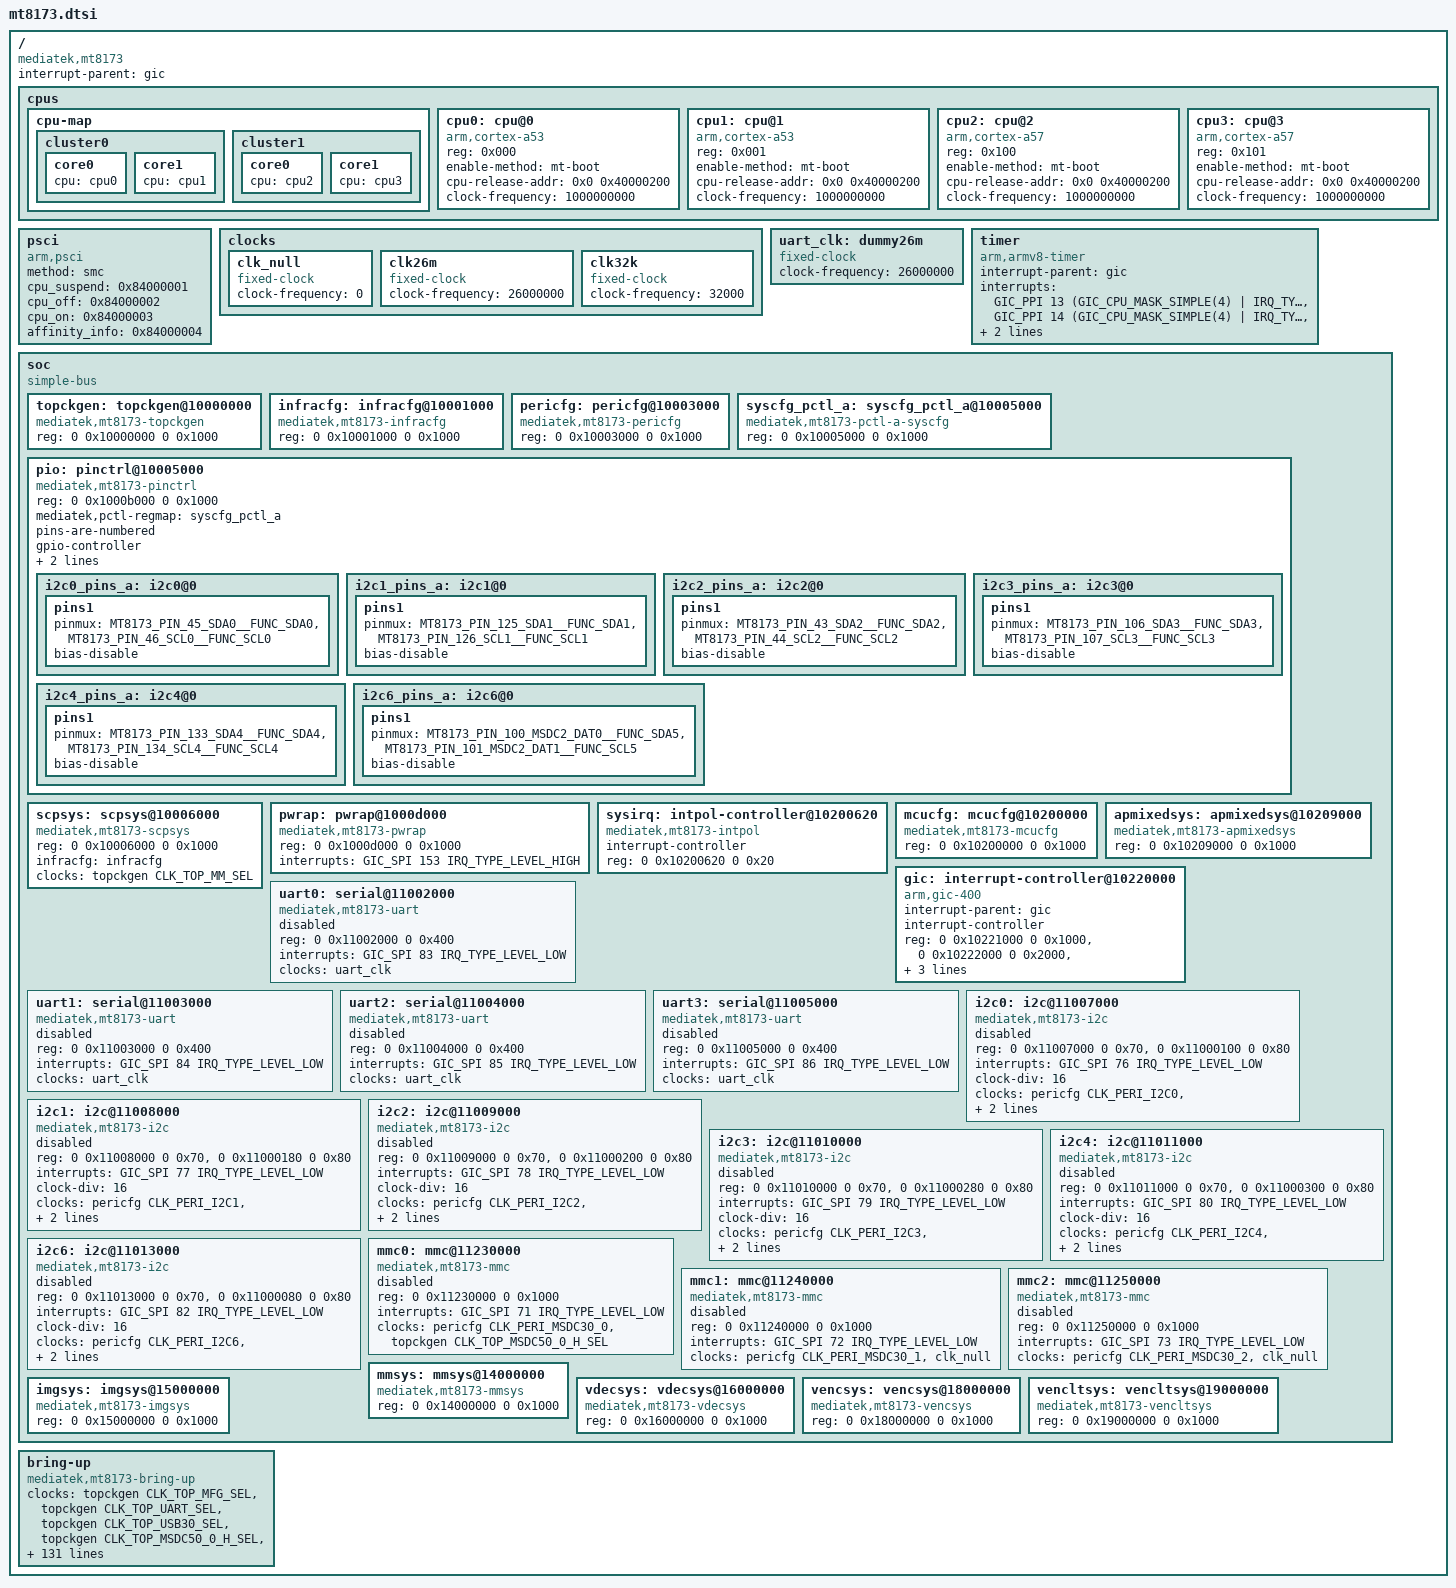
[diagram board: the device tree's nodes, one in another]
/*
 * Copyright (c) 2014 MediaTek Inc.
 * Author: Eddie Huang <eddie.huang@mediatek.com>
 *
 * This program is free software; you can redistribute it and/or modify
 * it under the terms of the GNU General Public License version 2 as
 * published by the Free Software Foundation.
 *
 * This program is distributed in the hope that it will be useful,
 * MERCHANTABILITY or FITNESS FOR A PARTICULAR PURPOSE.  See the
 * GNU General Public License for more details.
 */

#include <dt-bindings/interrupt-controller/irq.h>
#include <dt-bindings/interrupt-controller/arm-gic.h>
#include <dt-bindings/reset-controller/mt8173-resets.h>
#include <dt-bindings/clock/mt8173-clk.h>
#include <dt-bindings/power/mt8173-power.h>
#include "mt8173-pinfunc.h"

/ {
	compatible = "mediatek,mt8173";
	interrupt-parent = <&gic>;
	#address-cells = <2>;
	#size-cells = <2>;

	cpus {
		#address-cells = <1>;
		#size-cells = <0>;

		cpu-map {
			cluster0 {
				core0 {
					cpu = <&cpu0>;
				};
				core1 {
					cpu = <&cpu1>;
				};
			};

			cluster1 {
				core0 {
					cpu = <&cpu2>;
				};
				core1 {
					cpu = <&cpu3>;
				};
			};
		};

		cpu0: cpu@0 {
			device_type = "cpu";
			compatible = "arm,cortex-a53";
			reg = <0x000>;
			enable-method = "mt-boot";
			cpu-release-addr = <0x0 0x40000200>;
			clock-frequency = <1000000000>;
		};

		cpu1: cpu@1 {
			device_type = "cpu";
			compatible = "arm,cortex-a53";
			reg = <0x001>;
			enable-method = "mt-boot";
			cpu-release-addr = <0x0 0x40000200>;
			clock-frequency = <1000000000>;
		};

		cpu2: cpu@2 {
			device_type = "cpu";
			compatible = "arm,cortex-a57";
			reg = <0x100>;
			enable-method = "mt-boot";
			cpu-release-addr = <0x0 0x40000200>;
			clock-frequency = <1000000000>;
		};

		cpu3: cpu@3 {
			device_type = "cpu";
			compatible = "arm,cortex-a57";
			reg = <0x101>;
			enable-method = "mt-boot";
			cpu-release-addr = <0x0 0x40000200>;
			clock-frequency = <1000000000>;
		};
	};

	psci {
		compatible  = "arm,psci";
		method      = "smc";
		cpu_suspend = <0x84000001>;
		cpu_off     = <0x84000002>;
		cpu_on      = <0x84000003>;
		affinity_info = <0x84000004>;
	};

	clocks {
		clk_null: clk_null {
			compatible = "fixed-clock";
			#clock-cells = <0>;
			clock-frequency = <0>;
		};

		clk26m: clk26m {
			compatible = "fixed-clock";
			#clock-cells = <0>;
			clock-frequency = <26000000>;
		};

		clk32k: clk32k {
			compatible = "fixed-clock";
			#clock-cells = <0>;
			clock-frequency = <32000>;
		};
	};

	uart_clk: dummy26m {
		compatible = "fixed-clock";
		clock-frequency = <26000000>;
		#clock-cells = <0>;
	};

	timer {
		compatible = "arm,armv8-timer";
		interrupt-parent = <&gic>;
		interrupts = <GIC_PPI 13
			     (GIC_CPU_MASK_SIMPLE(4) | IRQ_TYPE_LEVEL_LOW)>,
			     <GIC_PPI 14
			     (GIC_CPU_MASK_SIMPLE(4) | IRQ_TYPE_LEVEL_LOW)>,
			     <GIC_PPI 11
			     (GIC_CPU_MASK_SIMPLE(4) | IRQ_TYPE_LEVEL_LOW)>,
			     <GIC_PPI 10
			     (GIC_CPU_MASK_SIMPLE(4) | IRQ_TYPE_LEVEL_LOW)>;
	};

	soc {
		#address-cells = <2>;
		#size-cells = <2>;
		compatible = "simple-bus";
		ranges;

		topckgen: topckgen@10000000 {
			compatible = "mediatek,mt8173-topckgen";
			reg = <0 0x10000000 0 0x1000>;
			#clock-cells = <1>;
		};

		infracfg: infracfg@10001000 {
			compatible = "mediatek,mt8173-infracfg", "syscon";
			reg = <0 0x10001000 0 0x1000>;
			#clock-cells = <1>;
			#reset-cells = <1>;
		};

		pericfg: pericfg@10003000 {
			compatible = "mediatek,mt8173-pericfg", "syscon";
			reg = <0 0x10003000 0 0x1000>;
			#clock-cells = <1>;
			#reset-cells = <1>;
		};

		syscfg_pctl_a: syscfg_pctl_a@10005000 {
			compatible = "mediatek,mt8173-pctl-a-syscfg", "syscon";
			reg = <0 0x10005000 0 0x1000>;
		};

		pio: pinctrl@10005000 {
			compatible = "mediatek,mt8173-pinctrl";
			reg = <0 0x1000b000 0 0x1000>;
			mediatek,pctl-regmap = <&syscfg_pctl_a>;
			pins-are-numbered;
			gpio-controller;
			#gpio-cells = <2>;
			interrupt-controller;
			#interrupt-cells = <2>;
			interrupts = <GIC_SPI 153 IRQ_TYPE_LEVEL_HIGH>;

			i2c0_pins_a: i2c0@0 {
				pins1 {
					pinmux = <MT8173_PIN_45_SDA0__FUNC_SDA0>,
						 <MT8173_PIN_46_SCL0__FUNC_SCL0>;
					bias-disable;
				};
			};

			i2c1_pins_a: i2c1@0 {
				pins1 {
					pinmux = <MT8173_PIN_125_SDA1__FUNC_SDA1>,
						 <MT8173_PIN_126_SCL1__FUNC_SCL1>;
					bias-disable;
				};
			};

			i2c2_pins_a: i2c2@0 {
				pins1 {
					pinmux = <MT8173_PIN_43_SDA2__FUNC_SDA2>,
						 <MT8173_PIN_44_SCL2__FUNC_SCL2>;
					bias-disable;
				};
			};

			i2c3_pins_a: i2c3@0 {
				pins1 {
					pinmux = <MT8173_PIN_106_SDA3__FUNC_SDA3>,
						 <MT8173_PIN_107_SCL3__FUNC_SCL3>;
					bias-disable;
				};
			};

			i2c4_pins_a: i2c4@0 {
				pins1 {
					pinmux = <MT8173_PIN_133_SDA4__FUNC_SDA4>,
						 <MT8173_PIN_134_SCL4__FUNC_SCL4>;
					bias-disable;
				};
			};

			i2c6_pins_a: i2c6@0 {
				pins1 {
					pinmux = <MT8173_PIN_100_MSDC2_DAT0__FUNC_SDA5>,
						 <MT8173_PIN_101_MSDC2_DAT1__FUNC_SCL5>;
					bias-disable;
				};
			};
		};

		scpsys: scpsys@10006000 {
			compatible = "mediatek,mt8173-scpsys", "syscon";
			#power-domain-cells = <1>;
			reg = <0 0x10006000 0 0x1000>;
			infracfg = <&infracfg>;
			clocks = <&topckgen CLK_TOP_MM_SEL>;
			clock-names = "disp";
		};

		pwrap: pwrap@1000d000 {
			compatible = "mediatek,mt8173-pwrap";
			reg = <0 0x1000d000 0 0x1000>;
			reg-names = "pwrap-base";
			interrupts = <GIC_SPI 153 IRQ_TYPE_LEVEL_HIGH>;
		};

		sysirq: intpol-controller@10200620 {
			compatible = "mediatek,mt8173-intpol",
				     "mediatek,mt6577-intpol";
			interrupt-controller;
			reg = <0 0x10200620 0 0x20>;
		};

		mcucfg: mcucfg@10200000 {
			compatible = "mediatek,mt8173-mcucfg", "syscon";
			reg = <0 0x10200000 0 0x1000>;
		};

		apmixedsys: apmixedsys@10209000 {
			compatible = "mediatek,mt8173-apmixedsys";
			reg = <0 0x10209000 0 0x1000>;
			#clock-cells = <1>;
		};

		gic: interrupt-controller@10220000 {
			compatible = "arm,gic-400";
			#interrupt-cells = <3>;
			interrupt-parent = <&gic>;
			interrupt-controller;
			reg = <0 0x10221000 0 0x1000>,
			      <0 0x10222000 0 0x2000>,
			      <0 0x10224000 0 0x2000>,
			      <0 0x10226000 0 0x2000>;
			interrupts = <GIC_PPI 9
				     (GIC_CPU_MASK_SIMPLE(4) | IRQ_TYPE_LEVEL_HIGH)>;
		};

		uart0: serial@11002000 {
			compatible = "mediatek,mt8173-uart",
				     "mediatek,mt6577-uart";
			reg = <0 0x11002000 0 0x400>;
			interrupts = <GIC_SPI 83 IRQ_TYPE_LEVEL_LOW>;
			clocks = <&uart_clk>;
			clock-names = "baud";
			status = "disabled";
		};

		uart1: serial@11003000 {
			compatible = "mediatek,mt8173-uart",
				     "mediatek,mt6577-uart";
			reg = <0 0x11003000 0 0x400>;
			interrupts = <GIC_SPI 84 IRQ_TYPE_LEVEL_LOW>;
			clocks = <&uart_clk>;
			clock-names = "baud";
			status = "disabled";
		};

		uart2: serial@11004000 {
			compatible = "mediatek,mt8173-uart",
				     "mediatek,mt6577-uart";
			reg = <0 0x11004000 0 0x400>;
			interrupts = <GIC_SPI 85 IRQ_TYPE_LEVEL_LOW>;
			clocks = <&uart_clk>;
			clock-names = "baud";
			status = "disabled";
		};

		uart3: serial@11005000 {
			compatible = "mediatek,mt8173-uart",
				     "mediatek,mt6577-uart";
			reg = <0 0x11005000 0 0x400>;
			interrupts = <GIC_SPI 86 IRQ_TYPE_LEVEL_LOW>;
			clocks = <&uart_clk>;
			clock-names = "baud";
			status = "disabled";
		};

		i2c0: i2c@11007000 {
			compatible = "mediatek,mt8173-i2c";
			reg = <0 0x11007000 0 0x70>,
			      <0 0x11000100 0 0x80>;
			interrupts = <GIC_SPI 76 IRQ_TYPE_LEVEL_LOW>;
			clock-div = <16>;
			clocks = <&pericfg CLK_PERI_I2C0>, <&pericfg CLK_PERI_AP_DMA>;
			clock-names = "main", "dma";
			pinctrl-names = "default";
			pinctrl-0 = <&i2c0_pins_a>;
			#address-cells = <1>;
			#size-cells = <0>;
			status = "disabled";
		};

		i2c1: i2c@11008000 {
			compatible = "mediatek,mt8173-i2c";
			reg = <0 0x11008000 0 0x70>,
			      <0 0x11000180 0 0x80>;
			interrupts = <GIC_SPI 77 IRQ_TYPE_LEVEL_LOW>;
			clock-div = <16>;
			clocks = <&pericfg CLK_PERI_I2C1>, <&pericfg CLK_PERI_AP_DMA>;
			clock-names = "main", "dma";
			pinctrl-names = "default";
			pinctrl-0 = <&i2c1_pins_a>;
			#address-cells = <1>;
			#size-cells = <0>;
			status = "disabled";
		};

		i2c2: i2c@11009000 {
			compatible = "mediatek,mt8173-i2c";
			reg = <0 0x11009000 0 0x70>,
			      <0 0x11000200 0 0x80>;
			interrupts = <GIC_SPI 78 IRQ_TYPE_LEVEL_LOW>;
			clock-div = <16>;
			clocks = <&pericfg CLK_PERI_I2C2>, <&pericfg CLK_PERI_AP_DMA>;
			clock-names = "main", "dma";
			pinctrl-names = "default";
			pinctrl-0 = <&i2c2_pins_a>;
			#address-cells = <1>;
			#size-cells = <0>;
			status = "disabled";
		};

		i2c3: i2c@11010000 {
			compatible = "mediatek,mt8173-i2c";
			reg = <0 0x11010000 0 0x70>,
			      <0 0x11000280 0 0x80>;
			interrupts = <GIC_SPI 79 IRQ_TYPE_LEVEL_LOW>;
			clock-div = <16>;
			clocks = <&pericfg CLK_PERI_I2C3>, <&pericfg CLK_PERI_AP_DMA>;
			clock-names = "main", "dma";
			pinctrl-names = "default";
			pinctrl-0 = <&i2c3_pins_a>;
			#address-cells = <1>;
			#size-cells = <0>;
			status = "disabled";
		};

		i2c4: i2c@11011000 {
			compatible = "mediatek,mt8173-i2c";
			reg = <0 0x11011000 0 0x70>,
			      <0 0x11000300 0 0x80>;
			interrupts = <GIC_SPI 80 IRQ_TYPE_LEVEL_LOW>;
			clock-div = <16>;
			clocks = <&pericfg CLK_PERI_I2C4>, <&pericfg CLK_PERI_AP_DMA>;
			clock-names = "main", "dma";
			pinctrl-names = "default";
			pinctrl-0 = <&i2c4_pins_a>;
			#address-cells = <1>;
			#size-cells = <0>;
			status = "disabled";
		};

		i2c6: i2c@11013000 {
			compatible = "mediatek,mt8173-i2c";
			reg = <0 0x11013000 0 0x70>,
			      <0 0x11000080 0 0x80>;
			interrupts = <GIC_SPI 82 IRQ_TYPE_LEVEL_LOW>;
			clock-div = <16>;
			clocks = <&pericfg CLK_PERI_I2C6>, <&pericfg CLK_PERI_AP_DMA>;
			clock-names = "main", "dma";
			pinctrl-names = "default";
			pinctrl-0 = <&i2c6_pins_a>;
			#address-cells = <1>;
			#size-cells = <0>;
			status = "disabled";
		};

		mmc0: mmc@11230000 {
			compatible = "mediatek,mt8173-mmc",
				     "mediatek,mt8135-mmc";
			reg = <0 0x11230000 0 0x1000>;
			interrupts = <GIC_SPI 71 IRQ_TYPE_LEVEL_LOW>;
			clocks = <&pericfg CLK_PERI_MSDC30_0>,
				 <&topckgen CLK_TOP_MSDC50_0_H_SEL>;
			clock-names = "source", "hclk";
			status = "disabled";
		};

		mmc1: mmc@11240000 {
			compatible = "mediatek,mt8173-mmc",
				     "mediatek,mt8135-mmc";
			reg = <0 0x11240000 0 0x1000>;
			interrupts = <GIC_SPI 72 IRQ_TYPE_LEVEL_LOW>;
			clocks = <&pericfg CLK_PERI_MSDC30_1>,
				 <&clk_null>;
			clock-names = "source", "hclk";
			status = "disabled";
		};

		mmc2: mmc@11250000 {
			compatible = "mediatek,mt8173-mmc",
				     "mediatek,mt8135-mmc";
			reg = <0 0x11250000 0 0x1000>;
			interrupts = <GIC_SPI 73 IRQ_TYPE_LEVEL_LOW>;
			clocks = <&pericfg CLK_PERI_MSDC30_2>,
				 <&clk_null>;
			clock-names = "source", "hclk";
			status = "disabled";
		};

		mmsys: mmsys@14000000 {
			compatible = "mediatek,mt8173-mmsys", "syscon";
			reg = <0 0x14000000 0 0x1000>;
			#clock-cells = <1>;
		};

		imgsys: imgsys@15000000 {
			compatible = "mediatek,mt8173-imgsys", "syscon";
			reg = <0 0x15000000 0 0x1000>;
			#clock-cells = <1>;
		};

		vdecsys: vdecsys@16000000 {
			compatible = "mediatek,mt8173-vdecsys", "syscon";
			reg = <0 0x16000000 0 0x1000>;
			#clock-cells = <1>;
		};

		vencsys: vencsys@18000000 {
			compatible = "mediatek,mt8173-vencsys", "syscon";
			reg = <0 0x18000000 0 0x1000>;
			#clock-cells = <1>;
		};

		vencltsys: vencltsys@19000000 {
			compatible = "mediatek,mt8173-vencltsys", "syscon";
			reg = <0 0x19000000 0 0x1000>;
			#clock-cells = <1>;
		};
	};

	bring-up {
		compatible = "mediatek,mt8173-bring-up";
		clocks =
			<&topckgen CLK_TOP_MFG_SEL>,
			<&topckgen CLK_TOP_UART_SEL>,
			<&topckgen CLK_TOP_USB30_SEL>,
			<&topckgen CLK_TOP_MSDC50_0_H_SEL>,
			<&topckgen CLK_TOP_AUDIO_SEL>,
			<&topckgen CLK_TOP_SCP_SEL>,
			<&topckgen CLK_TOP_ATB_SEL>,
			<&topckgen CLK_TOP_AUD_1_SEL>,
			<&topckgen CLK_TOP_AUD_2_SEL>,
			<&topckgen CLK_TOP_MEM_MFG_IN_SEL>,
			<&topckgen CLK_TOP_AXI_MFG_IN_SEL>,
			<&topckgen CLK_TOP_SCAM_SEL>,
			<&topckgen CLK_TOP_SPINFI_IFR_SEL>,
			<&topckgen CLK_TOP_DPILVDS_SEL>,
			<&topckgen CLK_TOP_MSDC50_2_H_SEL>,
			<&infracfg CLK_INFRA_DBGCLK>,
			<&infracfg CLK_INFRA_SMI>,
			<&infracfg CLK_INFRA_AUDIO>,
			<&infracfg CLK_INFRA_GCE>,
			<&infracfg CLK_INFRA_L2C_SRAM>,
			<&infracfg CLK_INFRA_M4U>,
			<&infracfg CLK_INFRA_CPUM>,
			<&infracfg CLK_INFRA_KP>,
			<&infracfg CLK_INFRA_CEC>,
			<&infracfg CLK_INFRA_PMICSPI>,
			<&infracfg CLK_INFRA_PMICWRAP>,
			<&infracfg CLK_INFRA_NR_CLK>,
			<&pericfg CLK_PERI_NFI>,
			<&pericfg CLK_PERI_THERM>,
			<&pericfg CLK_PERI_PWM1>,
			<&pericfg CLK_PERI_PWM2>,
			<&pericfg CLK_PERI_PWM3>,
			<&pericfg CLK_PERI_PWM4>,
			<&pericfg CLK_PERI_PWM5>,
			<&pericfg CLK_PERI_PWM6>,
			<&pericfg CLK_PERI_PWM7>,
			<&pericfg CLK_PERI_PWM>,
			<&pericfg CLK_PERI_USB0>,
			<&pericfg CLK_PERI_USB1>,
			<&pericfg CLK_PERI_AP_DMA>,
			<&pericfg CLK_PERI_MSDC30_0>,
			<&pericfg CLK_PERI_MSDC30_1>,
			<&pericfg CLK_PERI_MSDC30_2>,
			<&pericfg CLK_PERI_MSDC30_3>,
			<&pericfg CLK_PERI_NLI_ARB>,
			<&pericfg CLK_PERI_IRDA>,
			<&pericfg CLK_PERI_UART0>,
			<&pericfg CLK_PERI_UART1>,
			<&pericfg CLK_PERI_UART2>,
			<&pericfg CLK_PERI_UART3>,
			<&pericfg CLK_PERI_I2C0>,
			<&pericfg CLK_PERI_I2C1>,
			<&pericfg CLK_PERI_I2C2>,
			<&pericfg CLK_PERI_I2C3>,
			<&pericfg CLK_PERI_I2C4>,
			<&pericfg CLK_PERI_AUXADC>,
			<&pericfg CLK_PERI_SPI0>,
			<&pericfg CLK_PERI_I2C5>,
			<&pericfg CLK_PERI_NFIECC>,
			<&pericfg CLK_PERI_SPI>,
			<&pericfg CLK_PERI_IRRX>,
			<&pericfg CLK_PERI_I2C6>,
			<&pericfg CLK_PERI_UART0_SEL>,
			<&pericfg CLK_PERI_UART1_SEL>,
			<&pericfg CLK_PERI_UART2_SEL>,
			<&pericfg CLK_PERI_UART3_SEL>,
			<&pericfg CLK_PERI_NR_CLK>,
			<&imgsys CLK_IMG_LARB2_SMI>,
			<&imgsys CLK_IMG_CAM_SMI>,
			<&imgsys CLK_IMG_CAM_CAM>,
			<&imgsys CLK_IMG_SEN_TG>,
			<&imgsys CLK_IMG_SEN_CAM>,
			<&imgsys CLK_IMG_CAM_SV>,
			<&imgsys CLK_IMG_FD>,
			<&imgsys CLK_IMG_NR_CLK>,
			<&mmsys CLK_MM_SMI_COMMON>,
			<&mmsys CLK_MM_SMI_LARB0>,
			<&mmsys CLK_MM_CAM_MDP>,
			<&mmsys CLK_MM_MDP_RDMA0>,
			<&mmsys CLK_MM_MDP_RDMA1>,
			<&mmsys CLK_MM_MDP_RSZ0>,
			<&mmsys CLK_MM_MDP_RSZ1>,
			<&mmsys CLK_MM_MDP_RSZ2>,
			<&mmsys CLK_MM_MDP_TDSHP0>,
			<&mmsys CLK_MM_MDP_TDSHP1>,
			<&mmsys CLK_MM_MDP_WDMA>,
			<&mmsys CLK_MM_MDP_WROT0>,
			<&mmsys CLK_MM_MDP_WROT1>,
			<&mmsys CLK_MM_FAKE_ENG>,
			<&mmsys CLK_MM_MUTEX_32K>,
			<&mmsys CLK_MM_DISP_OVL0>,
			<&mmsys CLK_MM_DISP_OVL1>,
			<&mmsys CLK_MM_DISP_RDMA0>,
			<&mmsys CLK_MM_DISP_RDMA1>,
			<&mmsys CLK_MM_DISP_RDMA2>,
			<&mmsys CLK_MM_DISP_WDMA0>,
			<&mmsys CLK_MM_DISP_WDMA1>,
			<&mmsys CLK_MM_DISP_COLOR0>,
			<&mmsys CLK_MM_DISP_COLOR1>,
			<&mmsys CLK_MM_DISP_AAL>,
			<&mmsys CLK_MM_DISP_GAMMA>,
			<&mmsys CLK_MM_DISP_UFOE>,
			<&mmsys CLK_MM_DISP_SPLIT0>,
			<&mmsys CLK_MM_DISP_SPLIT1>,
			<&mmsys CLK_MM_DISP_MERGE>,
			<&mmsys CLK_MM_DISP_OD>,
			<&mmsys CLK_MM_DISP_PWM0MM>,
			<&mmsys CLK_MM_DISP_PWM026M>,
			<&mmsys CLK_MM_DISP_PWM1MM>,
			<&mmsys CLK_MM_DISP_PWM126M>,
			<&mmsys CLK_MM_DSI0_ENGINE>,
			<&mmsys CLK_MM_DSI0_DIGITAL>,
			<&mmsys CLK_MM_DSI1_ENGINE>,
			<&mmsys CLK_MM_DSI1_DIGITAL>,
			<&mmsys CLK_MM_DPI_PIXEL>,
			<&mmsys CLK_MM_DPI_ENGINE>,
			<&mmsys CLK_MM_DPI1_PIXEL>,
			<&mmsys CLK_MM_DPI1_ENGINE>,
			<&mmsys CLK_MM_HDMI_PIXEL>,
			<&mmsys CLK_MM_HDMI_PLLCK>,
			<&mmsys CLK_MM_HDMI_AUDIO>,
			<&mmsys CLK_MM_HDMI_SPDIF>,
			<&mmsys CLK_MM_LVDS_PIXEL>,
			<&mmsys CLK_MM_LVDS_CTS>,
			<&mmsys CLK_MM_SMI_LARB4>,
			<&mmsys CLK_MM_HDMI_HDCP>,
			<&mmsys CLK_MM_HDMI_HDCP24M>,
			<&mmsys CLK_MM_NR_CLK>,
			<&vdecsys CLK_VDEC_CKEN>,
			<&vdecsys CLK_VDEC_LARB_CKEN>,
			<&vdecsys CLK_VDEC_NR_CLK>,
			<&vencsys CLK_VENC_CKE0>,
			<&vencsys CLK_VENC_CKE1>,
			<&vencsys CLK_VENC_CKE2>,
			<&vencsys CLK_VENC_CKE3>,
			<&vencsys CLK_VENC_NR_CLK>,
			<&vencltsys CLK_VENCLT_CKE0>,
			<&vencltsys CLK_VENCLT_CKE1>,
			<&vencltsys CLK_VENCLT_NR_CLK>,
			<&clk_null>;

		clock-names =
			"0", "1", "2", "3", "4", "5", "6", "7", "8", "9", "10",
			"11", "12", "13", "14", "15", "16", "17", "18", "19", "20",
			"21", "22", "23", "24", "25", "26", "27", "28", "29", "30",
			"31", "32", "33", "34", "35", "36", "37", "38", "39", "40",
			"41", "42", "43", "44", "45", "46", "47", "48", "49", "50",
			"51", "52", "53", "54", "55", "56", "57", "58", "59", "60",
			"61", "62", "63", "64", "65", "66", "67", "68", "69", "70",
			"71", "72", "73", "74", "75", "76", "77", "78", "79", "80",
			"81", "82", "83", "84", "85", "86", "87", "88", "89", "90",
			"91", "92", "93", "94", "95", "96", "97", "98", "99", "100",
			"101", "102", "103", "104", "105", "106", "107", "108", "109", "110",
			"111", "112", "113", "114", "115", "116", "117", "118", "119", "120",
			"121", "122", "123", "124", "125", "126", "127", "128", "129", "130",
			"131", "132", "133", "134", "135", "136", "137", "138", "139", "140";
	};
};

